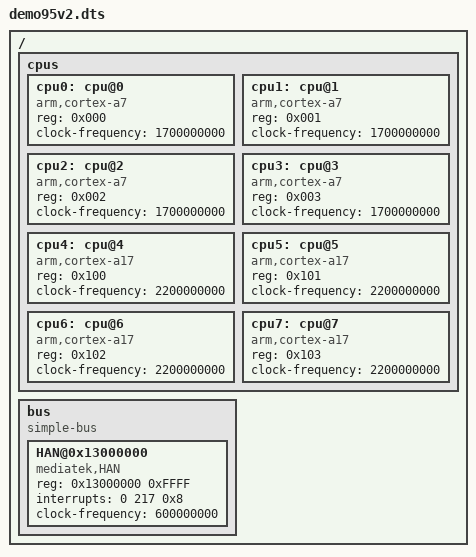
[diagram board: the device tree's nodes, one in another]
/*
 * Mediatek's MT6595 SoC device tree source
 *
 * Copyright (c) 2013 MediaTek Co., Ltd.
 *              http://www.mediatek.com
 *
 */

/dts-v1/;
/include/ "mt6595.dtsi"
/include/ "cust_eint.dtsi"

/ {
		cpus {
		#address-cells = <1>;
		#size-cells = <0>;

		cpu0: cpu@0 {
			device_type = "cpu";
			compatible = "arm,cortex-a7";
			reg = <0x000>;
			clock-frequency = <1700000000>;
		};

		cpu1: cpu@1 {
			device_type = "cpu";
			compatible = "arm,cortex-a7";
			reg = <0x001>;
			clock-frequency = <1700000000>;
		};

		cpu2: cpu@2 {
			device_type = "cpu";
			compatible = "arm,cortex-a7";
			reg = <0x002>;
			clock-frequency = <1700000000>;
		};

		cpu3: cpu@3 {
			device_type = "cpu";
			compatible = "arm,cortex-a7";
			reg = <0x003>;
			clock-frequency = <1700000000>;
		};

		cpu4: cpu@4 {
			device_type = "cpu";
			compatible = "arm,cortex-a17";
			reg = <0x100>;
			clock-frequency = <2200000000>;
		};

		cpu5: cpu@5 {
			device_type = "cpu";
			compatible = "arm,cortex-a17";
			reg = <0x101>;
			clock-frequency = <2200000000>;
		};

		cpu6: cpu@6 {
			device_type = "cpu";
			compatible = "arm,cortex-a17";
			reg = <0x102>;
			clock-frequency = <2200000000>;
		};

		cpu7: cpu@7 {
			device_type = "cpu";
			compatible = "arm,cortex-a17";
			reg = <0x103>;
			clock-frequency = <2200000000>;
		};

	};
	bus {
		compatible = "simple-bus";
		#address-cells = <1>;
		#size-cells = <1>;
		ranges = <0 0 0 0xffffffff>;
		
		HAN@0x13000000 {
			compatible = "mediatek,HAN";
			reg = <0x13000000 0xFFFF>;
			interrupts = <0 217 0x8>;
			interrupt-names = "RGX";
			clock-frequency = <600000000>;
		};
	};
};
